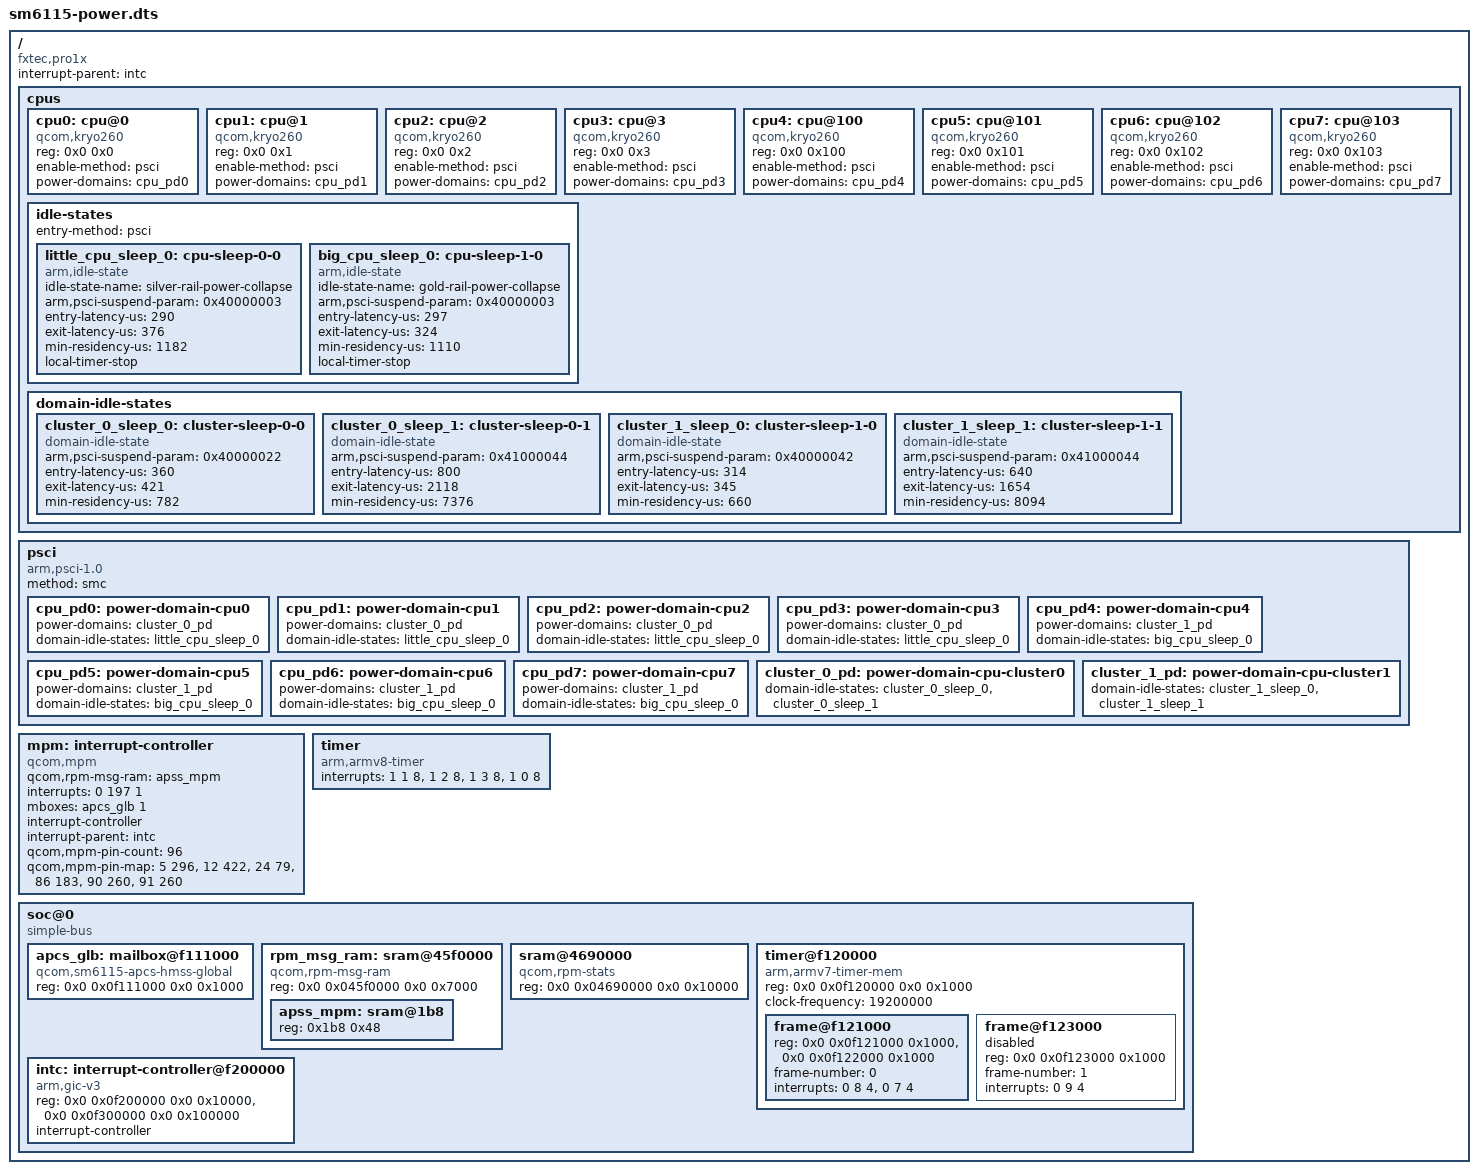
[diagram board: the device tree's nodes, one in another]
// SPDX-License-Identifier: (GPL-2.0+ OR BSD-3-Clause)
/*
 * The parts of the SM6115's device tree that KolibriOS's power management
 * reads (tests/power/host.c), copied from Linux's
 * arch/arm64/boot/dts/qcom/sm6115.dtsi (Copyright (c) 2021, Iskren
 * Chernev; with pro1x-maemo-leste's patches 0006/0009/0011: the MPM),
 * the macros written out (GIC_SPI 0, GIC_PPI 1; IRQ_TYPE_EDGE_RISING 1,
 * IRQ_TYPE_LEVEL_HIGH 4, IRQ_TYPE_LEVEL_LOW 8).
 */
/dts-v1/;

/ {
	#address-cells = <2>;
	#size-cells = <2>;
	interrupt-parent = <&intc>;
	compatible = "fxtec,pro1x", "qcom,sm6115";

	cpus {
		#address-cells = <2>;
		#size-cells = <0>;

		cpu0: cpu@0 {
			device_type = "cpu";
			compatible = "qcom,kryo260";
			reg = <0x0 0x0>;
			enable-method = "psci";
			power-domains = <&cpu_pd0>;
			power-domain-names = "psci";
		};
		cpu1: cpu@1 {
			device_type = "cpu";
			compatible = "qcom,kryo260";
			reg = <0x0 0x1>;
			enable-method = "psci";
			power-domains = <&cpu_pd1>;
			power-domain-names = "psci";
		};
		cpu2: cpu@2 {
			device_type = "cpu";
			compatible = "qcom,kryo260";
			reg = <0x0 0x2>;
			enable-method = "psci";
			power-domains = <&cpu_pd2>;
			power-domain-names = "psci";
		};
		cpu3: cpu@3 {
			device_type = "cpu";
			compatible = "qcom,kryo260";
			reg = <0x0 0x3>;
			enable-method = "psci";
			power-domains = <&cpu_pd3>;
			power-domain-names = "psci";
		};
		cpu4: cpu@100 {
			device_type = "cpu";
			compatible = "qcom,kryo260";
			reg = <0x0 0x100>;
			enable-method = "psci";
			power-domains = <&cpu_pd4>;
			power-domain-names = "psci";
		};
		cpu5: cpu@101 {
			device_type = "cpu";
			compatible = "qcom,kryo260";
			reg = <0x0 0x101>;
			enable-method = "psci";
			power-domains = <&cpu_pd5>;
			power-domain-names = "psci";
		};
		cpu6: cpu@102 {
			device_type = "cpu";
			compatible = "qcom,kryo260";
			reg = <0x0 0x102>;
			enable-method = "psci";
			power-domains = <&cpu_pd6>;
			power-domain-names = "psci";
		};
		cpu7: cpu@103 {
			device_type = "cpu";
			compatible = "qcom,kryo260";
			reg = <0x0 0x103>;
			enable-method = "psci";
			power-domains = <&cpu_pd7>;
			power-domain-names = "psci";
		};

		idle-states {
			entry-method = "psci";

			little_cpu_sleep_0: cpu-sleep-0-0 {
				compatible = "arm,idle-state";
				idle-state-name = "silver-rail-power-collapse";
				arm,psci-suspend-param = <0x40000003>;
				entry-latency-us = <290>;
				exit-latency-us = <376>;
				min-residency-us = <1182>;
				local-timer-stop;
			};

			big_cpu_sleep_0: cpu-sleep-1-0 {
				compatible = "arm,idle-state";
				idle-state-name = "gold-rail-power-collapse";
				arm,psci-suspend-param = <0x40000003>;
				entry-latency-us = <297>;
				exit-latency-us = <324>;
				min-residency-us = <1110>;
				local-timer-stop;
			};
		};

		domain-idle-states {
			cluster_0_sleep_0: cluster-sleep-0-0 {
				/* GDHS */
				compatible = "domain-idle-state";
				arm,psci-suspend-param = <0x40000022>;
				entry-latency-us = <360>;
				exit-latency-us = <421>;
				min-residency-us = <782>;
			};

			cluster_0_sleep_1: cluster-sleep-0-1 {
				/* Power Collapse */
				compatible = "domain-idle-state";
				arm,psci-suspend-param = <0x41000044>;
				entry-latency-us = <800>;
				exit-latency-us = <2118>;
				min-residency-us = <7376>;
			};

			cluster_1_sleep_0: cluster-sleep-1-0 {
				/* GDHS */
				compatible = "domain-idle-state";
				arm,psci-suspend-param = <0x40000042>;
				entry-latency-us = <314>;
				exit-latency-us = <345>;
				min-residency-us = <660>;
			};

			cluster_1_sleep_1: cluster-sleep-1-1 {
				/* Power Collapse */
				compatible = "domain-idle-state";
				arm,psci-suspend-param = <0x41000044>;
				entry-latency-us = <640>;
				exit-latency-us = <1654>;
				min-residency-us = <8094>;
			};
		};
	};

	psci {
		compatible = "arm,psci-1.0";
		method = "smc";

		cpu_pd0: power-domain-cpu0 {
			#power-domain-cells = <0>;
			power-domains = <&cluster_0_pd>;
			domain-idle-states = <&little_cpu_sleep_0>;
		};
		cpu_pd1: power-domain-cpu1 {
			#power-domain-cells = <0>;
			power-domains = <&cluster_0_pd>;
			domain-idle-states = <&little_cpu_sleep_0>;
		};
		cpu_pd2: power-domain-cpu2 {
			#power-domain-cells = <0>;
			power-domains = <&cluster_0_pd>;
			domain-idle-states = <&little_cpu_sleep_0>;
		};
		cpu_pd3: power-domain-cpu3 {
			#power-domain-cells = <0>;
			power-domains = <&cluster_0_pd>;
			domain-idle-states = <&little_cpu_sleep_0>;
		};
		cpu_pd4: power-domain-cpu4 {
			#power-domain-cells = <0>;
			power-domains = <&cluster_1_pd>;
			domain-idle-states = <&big_cpu_sleep_0>;
		};
		cpu_pd5: power-domain-cpu5 {
			#power-domain-cells = <0>;
			power-domains = <&cluster_1_pd>;
			domain-idle-states = <&big_cpu_sleep_0>;
		};
		cpu_pd6: power-domain-cpu6 {
			#power-domain-cells = <0>;
			power-domains = <&cluster_1_pd>;
			domain-idle-states = <&big_cpu_sleep_0>;
		};
		cpu_pd7: power-domain-cpu7 {
			#power-domain-cells = <0>;
			power-domains = <&cluster_1_pd>;
			domain-idle-states = <&big_cpu_sleep_0>;
		};

		cluster_0_pd: power-domain-cpu-cluster0 {
			#power-domain-cells = <0>;
			domain-idle-states = <&cluster_0_sleep_0>, <&cluster_0_sleep_1>;
		};

		cluster_1_pd: power-domain-cpu-cluster1 {
			#power-domain-cells = <0>;
			domain-idle-states = <&cluster_1_sleep_0>, <&cluster_1_sleep_1>;
		};
	};

	mpm: interrupt-controller {
		compatible = "qcom,mpm";
		qcom,rpm-msg-ram = <&apss_mpm>;
		interrupts = <0 197 1>;
		mboxes = <&apcs_glb 1>;
		interrupt-controller;
		#interrupt-cells = <2>;
		interrupt-parent = <&intc>;
		qcom,mpm-pin-count = <96>;
		qcom,mpm-pin-map = <5 296>, <12 422>, <24 79>, <86 183>, <90 260>, <91 260>;
	};

	timer {
		compatible = "arm,armv8-timer";
		interrupts = <1 1 8>, <1 2 8>, <1 3 8>, <1 0 8>;
	};

	soc@0 {
		compatible = "simple-bus";
		#address-cells = <2>;
		#size-cells = <2>;
		ranges = <0 0 0 0 0x10 0>;

		apcs_glb: mailbox@f111000 {
			compatible = "qcom,sm6115-apcs-hmss-global", "qcom,msm8994-apcs-kpss-global";
			reg = <0x0 0x0f111000 0x0 0x1000>;
			#mbox-cells = <1>;
		};

		rpm_msg_ram: sram@45f0000 {
			compatible = "qcom,rpm-msg-ram", "mmio-sram";
			reg = <0x0 0x045f0000 0x0 0x7000>;
			#address-cells = <1>;
			#size-cells = <1>;
			ranges = <0 0x0 0x045f0000 0x7000>;

			apss_mpm: sram@1b8 {
				reg = <0x1b8 0x48>;
			};
		};

		sram@4690000 {
			compatible = "qcom,rpm-stats";
			reg = <0x0 0x04690000 0x0 0x10000>;
		};

		timer@f120000 {
			compatible = "arm,armv7-timer-mem";
			reg = <0x0 0x0f120000 0x0 0x1000>;
			#address-cells = <2>;
			#size-cells = <1>;
			ranges = <0x0 0x0 0x0 0x0 0x20000000>;
			clock-frequency = <19200000>;

			frame@f121000 {
				reg = <0x0 0x0f121000 0x1000>, <0x0 0x0f122000 0x1000>;
				frame-number = <0>;
				interrupts = <0 8 4>, <0 7 4>;
			};

			frame@f123000 {
				reg = <0x0 0x0f123000 0x1000>;
				frame-number = <1>;
				interrupts = <0 9 4>;
				status = "disabled";
			};
		};

		intc: interrupt-controller@f200000 {
			compatible = "arm,gic-v3";
			reg = <0x0 0x0f200000 0x0 0x10000>, <0x0 0x0f300000 0x0 0x100000>;
			#interrupt-cells = <3>;
			interrupt-controller;
		};
	};
};
